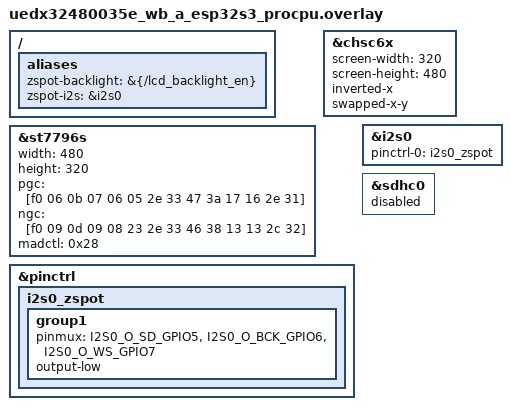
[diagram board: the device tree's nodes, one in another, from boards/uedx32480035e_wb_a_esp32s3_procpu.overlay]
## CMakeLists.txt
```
# Copyright (c) 2026 Muhammad Waleed Badar
# SPDX-License-Identifier: GPL-3.0-only

cmake_minimum_required(VERSION 3.20.0)

# When built from another west workspace, point Zephyr at this module.
if(NOT DEFINED ZEPHYR_EXTRA_MODULES)
  set(ZEPHYR_EXTRA_MODULES ${CMAKE_CURRENT_SOURCE_DIR}/..)
endif()

find_package(Zephyr REQUIRED HINTS $ENV{ZEPHYR_BASE})
project(zspot_player)

target_sources(app PRIVATE src/main.c)
target_sources_ifdef(CONFIG_WIFI_CREDENTIALS_CONNECT_STORED app PRIVATE src/wifi.c)
target_sources_ifdef(CONFIG_ZSPOT_PCM_TAP app PRIVATE src/pcm_tap.c)
target_sources_ifdef(CONFIG_ZSPOT_BATTERY app PRIVATE src/battery.c)
target_sources_ifdef(CONFIG_ZSPOT_UI app PRIVATE
  src/ui.c src/cover.c src/library.c src/webapi.c src/lyrics.c src/json_scan.c)
if(CONFIG_I2S_NATIVE_SIM)
  # Starts the host player the I2S driver writes into; built against the host
  # libc in the runner context.
  target_sources(native_simulator INTERFACE src/pcm_command_bottom.c)

  # Tell when the player is missing, rather than running without sound.
  if(NOT "${CONFIG_ZSPOT_PCM_COMMAND}" STREQUAL "")
    string(REGEX MATCH "^[^ ]+" pcm_player "${CONFIG_ZSPOT_PCM_COMMAND}")
    find_program(PCM_PLAYER_${pcm_player} ${pcm_player})
    if(NOT PCM_PLAYER_${pcm_player})
      message(WARNING "\"${pcm_player}\" (CONFIG_ZSPOT_PCM_COMMAND) was not found "
                      "on this host: the simulator will run without sound.")
    endif()
  endif()
endif()
```

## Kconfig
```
# Copyright (c) 2026 Muhammad Waleed Badar
# SPDX-License-Identifier: GPL-3.0-only

mainmenu "zspot player"

menu "zspot player"

config ZSPOT_PCM_COMMAND
	string "Host command that plays the audio (native_sim)"
	depends on I2S_NATIVE_SIM
	default "aplay -q -f S16_LE -r 44100 -c 2"
	help
	  On native_sim the audio goes through the file-backed I2S driver.
	  When this is set, the simulator starts the shell command at boot and
	  the driver writes into its standard input: raw 16-bit little-endian
	  stereo PCM at 44.1 kHz. Clear it to write the audio to the file
	  I2S_NATIVE_SIM_TX_FILE_PATH instead, or to the one given on the
	  command line with --<i2s device>_tx=<path>.

# The I2S driver opens a path: with a player, the pipe to its standard input
# is installed at this descriptor (src/pcm_command_bottom.c).
config I2S_NATIVE_SIM_TX_FILE_PATH
	default "/dev/fd/200" if ZSPOT_PCM_COMMAND != ""

config ZSPOT_PCM_TAP
	bool "PCM tap: copy of the audio over TCP"
	select RING_BUFFER_LARGE
	help
	  Starts a TCP server that sends a copy of the PCM handed to the sink
	  (16-bit little-endian stereo at 44.1 kHz, before the sink applies the
	  volume) to a client, to hear on another machine what the output is
	  fed with:

	    nc <device> <port> | aplay -f S16_LE -r 44100 -c 2 \
	        -B 1000000 -R 1000000

	  A diagnostic aid: when the copy sounds right but the DAC does not,
	  the fault is in the I2S configuration, the wiring or the DAC.

config ZSPOT_PCM_TAP_PORT
	int "TCP port of the PCM tap"
	default 5000
	depends on ZSPOT_PCM_TAP

config ZSPOT_USERNAME
	string "Spotify username (development only)"
	default ""
	help
	  Together with ZSPOT_PASSWORD, logs in with a username and
	  password instead of the zeroconf hand-over. Spotify no longer accepts
	  password logins from third-party clients for most accounts, but the
	  attempt still exercises access point resolution, the handshake and
	  the authentication exchange, which is useful on native_sim.

config ZSPOT_PASSWORD
	string "Spotify password (development only)"
	default ""

config ZSPOT_CREDENTIALS_JSON
	string "Stored credentials (JSON)"
	default ""
	help
	  Output of zspot_credentials_save_json() from a previous session. When
	  set, the sample skips the zeroconf hand-over.

# The defaults come from the environment of the build, so that the values stay
# out of the repository and of the command line.

config ZSPOT_WEB_CLIENT_ID
	string "Client ID of the Spotify developer application"
	default "$(ZSPOT_WEB_CLIENT_ID)"
	help
	  "Your Library" on the Now Playing screen uses the Spotify Web API,
	  which needs an application registered at developer.spotify.com and a
	  one-time authorisation by the user with scripts/spotify_authorize.py.
	  The three values default to the environment variables
	  ZSPOT_WEB_CLIENT_ID, ZSPOT_WEB_CLIENT_SECRET and
	  ZSPOT_WEB_REFRESH_TOKEN. Without them the library view only says that
	  it is not set up.

config ZSPOT_WEB_CLIENT_SECRET
	string "Client secret of the Spotify developer application"
	default "$(ZSPOT_WEB_CLIENT_SECRET)"

config ZSPOT_WEB_REFRESH_TOKEN
	string "Refresh token of the authorised user"
	default "$(ZSPOT_WEB_REFRESH_TOKEN)"

config ZSPOT_UI
	bool "Now Playing screen (LVGL)"
	depends on LVGL && LV_Z_RUN_LVGL_ON_WORKQUEUE && LV_USE_TJPGD
	help
	  Shows the cover art, title, artist and progress of the current track
	  on the chosen display (the layout follows its resolution) and offers touch
	  controls for play/pause, skipping, seeking and the volume. See
	  prj.conf for the LVGL configuration it needs.

if ZSPOT_UI

config ZSPOT_BATTERY
	bool "Battery indicator"
	default y
	depends on $(dt_alias_enabled,fuel-gauge0)
	select FUEL_GAUGE
	help
	  Shows the charge level reported by the fuel gauge behind the
	  devicetree alias fuel-gauge0 next to the network indicator. Only
	  available when the board has that alias and its node is enabled.

config ZSPOT_BATTERY_POLL_SECONDS
	int "Seconds between two readings of the fuel gauge"
	default 30
	range 1 3600

config ZSPOT_SCREEN_TIMEOUT_SECONDS
	int "Seconds without a touch after which the screen turns off"
	default 60
	range 0 3600
	help
	  Turns the display off, and its backlight when the board has the
	  devicetree alias zspot-backlight (a regulator), once the screen has
	  not been touched for this long. The next touch turns it back on and
	  does nothing else. Playback is not affected. 0 keeps the screen on.

endif # ZSPOT_UI

endmenu # zspot player

source "Kconfig.zephyr"
```

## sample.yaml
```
# Copyright (c) 2026 Muhammad Waleed Badar
# SPDX-License-Identifier: GPL-3.0-only

sample:
  name: zspot player
  description: Spotify Connect player with a touchscreen UI (Now Playing, library, lyrics, Wi-Fi setup)
tests:
  app.zspot.player:
    build_only: true
    tags: zspot
    platform_allow:
      - native_sim/native/64
      - uedx32480035e_wb_a/esp32s3/procpu
    integration_platforms:
      - native_sim/native/64
```

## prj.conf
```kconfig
# Copyright (c) 2026 Muhammad Waleed Badar
# SPDX-License-Identifier: GPL-3.0-only

# --- zspot ---------------------------------------------------------------
CONFIG_ZSPOT=y
CONFIG_ZSPOT_I2S_SINK=y

# --- C++ runtime for the protocol core -----------------------------------
CONFIG_CPP=y
CONFIG_STD_CPP20=y

# --- Memory ---------------------------------------------------------------
CONFIG_MAIN_STACK_SIZE=8192
# Wi-Fi connect requests run on the system workqueue; the ESP32 driver starts
# up in the caller's context and overflows the 1 KB default.
CONFIG_SYSTEM_WORKQUEUE_STACK_SIZE=4096
CONFIG_DYNAMIC_THREAD_POOL_SIZE=0
CONFIG_DYNAMIC_THREAD_PREFER_ALLOC=y

# --- Networking -----------------------------------------------------------
CONFIG_NETWORKING=y
CONFIG_NET_IPV4=y
CONFIG_NET_IPV6=n
CONFIG_NET_TCP=y
CONFIG_NET_UDP=y
CONFIG_NET_SOCKETS=y
CONFIG_NET_DHCPV4=y
CONFIG_NET_MGMT=y
CONFIG_NET_MGMT_EVENT=y
CONFIG_NET_MGMT_EVENT_INFO=y
CONFIG_NET_CONNECTION_MANAGER=n
CONFIG_NET_HOSTNAME_ENABLE=y
CONFIG_NET_HOSTNAME="zspot"
# The TCP receive window is a third of the RX buffer space (128 bytes each).
# With 64 buffers it was 2.7 KB, less than two segments, which throttled the
# audio download; 768 buffers make it 32 KB.
CONFIG_NET_PKT_RX_COUNT=64
CONFIG_NET_BUF_RX_COUNT=768
CONFIG_NET_PKT_TX_COUNT=64
CONFIG_NET_BUF_TX_COUNT=768
CONFIG_NET_MAX_CONN=12
CONFIG_NET_MAX_CONTEXTS=12

CONFIG_NET_RX_STACK_SIZE=4096
CONFIG_NET_TCP_WORKQ_STACK_SIZE=4096

CONFIG_ZVFS_OPEN_MAX=20
CONFIG_ZVFS_POLL_MAX=16

# DNS: resolver gets the servers from DHCP, static fallback below
CONFIG_DNS_RESOLVER=y
CONFIG_DNS_SERVER_IP_ADDRESSES=y
CONFIG_DNS_SERVER1="8.8.8.8"
CONFIG_DNS_RESOLVER_MAX_SERVERS=3
# At a track change the audio CDN, the cover, the lyrics and the Web API are
# looked up at the same time; with the default of one query at a time the
# others fail at once ("DNS lookup ... failed (-3)")
CONFIG_DNS_NUM_CONCUR_QUERIES=4

# mDNS / DNS-SD for discovery by the Spotify app
CONFIG_MDNS_RESPONDER=y
CONFIG_DNS_SD=y
CONFIG_MDNS_RESPONDER_DNS_SD=y

# --- TLS (Spotify endpoints: TLS 1.2, ECDHE-RSA, AES-GCM) -----------------
CONFIG_MBEDTLS=y
CONFIG_MBEDTLS_ENABLE_HEAP=y
# Sessions: access point resolution/metadata, audio CDN and the cover art
CONFIG_MBEDTLS_HEAP_SIZE=163840
CONFIG_MBEDTLS_SSL_IN_CONTENT_LEN=16384
CONFIG_MBEDTLS_SSL_OUT_CONTENT_LEN=4096
CONFIG_MBEDTLS_SSL_PROTO_TLS1_2=y
CONFIG_MBEDTLS_SSL_SERVER_NAME_INDICATION=y
CONFIG_MBEDTLS_KEY_EXCHANGE_ECDHE_RSA_ENABLED=y
CONFIG_MBEDTLS_CIPHERSUITE_TLS_ECDHE_RSA_WITH_AES_128_GCM_SHA256=y
CONFIG_MBEDTLS_CIPHERSUITE_TLS_ECDHE_RSA_WITH_AES_256_GCM_SHA384=y
# The lyrics service (lrclib.net) only offers ECDSA certificates
CONFIG_MBEDTLS_KEY_EXCHANGE_ECDHE_ECDSA_ENABLED=y
CONFIG_MBEDTLS_CIPHERSUITE_TLS_ECDHE_ECDSA_WITH_AES_128_GCM_SHA256=y
CONFIG_MBEDTLS_X509_CRT_PARSE_C=y
CONFIG_PSA_CRYPTO=y
CONFIG_PSA_WANT_ALG_SHA_256=y
CONFIG_PSA_WANT_ALG_SHA_384=y
CONFIG_PSA_WANT_ALG_GCM=y
CONFIG_PSA_WANT_ALG_ECDH=y
CONFIG_PSA_WANT_ECC_SECP_R1_256=y
CONFIG_PSA_WANT_ECC_SECP_R1_384=y
CONFIG_PSA_WANT_KEY_TYPE_ECC_KEY_PAIR_GENERATE=y
CONFIG_PSA_WANT_ALG_RSA_PKCS1V15_SIGN=y
CONFIG_PSA_WANT_ALG_ECDSA=y
CONFIG_PSA_WANT_KEY_TYPE_ECC_PUBLIC_KEY=y
CONFIG_PSA_WANT_KEY_TYPE_RSA_PUBLIC_KEY=y
CONFIG_NET_SOCKETS_SOCKOPT_TLS=y
CONFIG_NET_SOCKETS_TLS_MAX_CONTEXTS=6
CONFIG_ENTROPY_GENERATOR=y

# --- Display: "Now Playing" screen (LVGL) ----------------------------------
CONFIG_DISPLAY=y
CONFIG_INPUT=y
# Touch events queue up while the LVGL thread is busy (e.g. in a zspot call);
# with the default sizes drags lose events ("Could not put input data into
# queue")
CONFIG_INPUT_QUEUE_MAX_MSGS=64
CONFIG_LV_Z_POINTER_INPUT_MSGQ_COUNT=64
CONFIG_LVGL=y
CONFIG_LV_Z_POINTER_INPUT=y
# LVGL runs on its own workqueue; the touch handlers call into zspot from it
# (protobuf encoding, socket I/O), hence the stack
CONFIG_LV_Z_RUN_LVGL_ON_WORKQUEUE=y
CONFIG_LV_Z_LVGL_MUTEX=y
CONFIG_LV_Z_LVGL_WORKQUEUE_STACK_SIZE=16384
# Below the zspot threads (CONFIG_ZSPOT_THREAD_PRIORITY and higher): drawing
# must not take the processor from the audio decoder
CONFIG_LV_Z_LVGL_WORKQUEUE_PRIORITY=8
# Holds the widgets, the cover art (the downloaded JPEG, up to 96 KB, and the
# decoded RGB565 image, 180 KB at 300x300, briefly two of the latter), the
# Web API responses of the library view (160 KB) and the lyrics (80 KB while
# they load)
CONFIG_LV_Z_FLUSH_THREAD=y
CONFIG_LV_Z_FLUSH_THREAD_PRIORITY=8
CONFIG_LV_Z_MEM_POOL_SIZE=1048576
CONFIG_LV_USE_LABEL=y
CONFIG_LV_USE_IMAGE=y
CONFIG_LV_USE_BAR=y
CONFIG_LV_USE_SLIDER=y
# Password entry of the Wi-Fi settings
CONFIG_LV_USE_TEXTAREA=y
CONFIG_LV_USE_BUTTONMATRIX=y
CONFIG_LV_USE_KEYBOARD=y
CONFIG_LV_THEME_DEFAULT_DARK=y
CONFIG_LV_USE_TJPGD=y
CONFIG_LV_FONT_MONTSERRAT_12=y
CONFIG_LV_FONT_MONTSERRAT_14=y
CONFIG_LV_FONT_MONTSERRAT_20=y
CONFIG_LV_FONT_MONTSERRAT_28=y
# One and a half times and twice the size, for displays larger than the
# 320x480 the UI is drawn for (the layout scales with the resolution)
CONFIG_LV_FONT_MONTSERRAT_18=y
CONFIG_LV_FONT_MONTSERRAT_30=y
CONFIG_LV_FONT_MONTSERRAT_24=y
CONFIG_LV_FONT_MONTSERRAT_40=y
CONFIG_LV_FONT_MONTSERRAT_48=y
CONFIG_ZSPOT_UI=y

# --- Wi-Fi (wifi_credentials library, settings/NVS backend) ----------------
# The Wi-Fi driver is selected per board; boards without Wi-Fi override this
# block (see boards/native_sim_native_64.conf).
CONFIG_WIFI=y
CONFIG_WIFI_CREDENTIALS=y
CONFIG_WIFI_CREDENTIALS_CONNECT_STORED=y
CONFIG_FLASH=y
CONFIG_FLASH_MAP=y
CONFIG_NVS=y
CONFIG_SETTINGS=y
CONFIG_NET_MGMT_EVENT_QUEUE_SIZE=16
CONFIG_NET_MGMT_EVENT_STACK_SIZE=4096

# --- Speed ----------------------------------------------------------------
CONFIG_SPEED_OPTIMIZATIONS=y

# --- Logging --------------------------------------------------------------
# Off to save processor time and memory: the console then reports nothing,
# not even I2S underruns or fatal errors. To turn it on, build with
# CONFIG_LOG=y and, for the library, CONFIG_ZSPOT_LOG_LEVEL_INF=y.
CONFIG_NET_LOG=n
CONFIG_LOG_MODE_IMMEDIATE=n
```

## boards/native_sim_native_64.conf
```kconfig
# Copyright (c) 2026 Muhammad Waleed Badar
# SPDX-License-Identifier: GPL-3.0-only
#
# native_sim/native/64: Zephyr IP stack over the host TAP interface (zeth). Create it
# on the host first with net-tools: sudo tools/net-tools/net-setup.sh
# Zephyr uses 192.0.2.1, the host side is 192.0.2.2 (gateway and NAT).

CONFIG_NET_L2_ETHERNET=y
CONFIG_ETH_NATIVE_TAP=y
CONFIG_NET_DHCPV4=n
CONFIG_NET_CONFIG_SETTINGS=y
CONFIG_NET_CONFIG_NEED_IPV4=y
CONFIG_NET_CONFIG_MY_IPV4_ADDR="192.0.2.1"
CONFIG_NET_CONFIG_MY_IPV4_NETMASK="255.255.255.0"
CONFIG_NET_CONFIG_MY_IPV4_GW="192.0.2.2"
CONFIG_NET_CONFIG_PEER_IPV4_ADDR="192.0.2.2"

# No Wi-Fi and no flash-backed settings: override the generic Wi-Fi block
CONFIG_WIFI=n
CONFIG_WIFI_CREDENTIALS=n
CONFIG_WIFI_CREDENTIALS_CONNECT_STORED=n
CONFIG_SETTINGS=n
CONFIG_NVS=n
CONFIG_FLASH=n
CONFIG_FLASH_MAP=n

# The audio goes through the file-backed native_sim I2S driver (the zspot-i2s
# alias in the overlay) into the player named by CONFIG_ZSPOT_PCM_COMMAND, by
# default aplay (alsa-utils). Build with -DCONFIG_ZSPOT_PCM_COMMAND="" to write
# it to the file i2s_out.pcm, or the one given with --i2s_tx_tx=<path>, instead.
# Host RAM is plentiful: buffer ahead of the output as on the ESP32, so that
# the output keeps running while the player fetches the next piece of a track.
CONFIG_ZSPOT_I2S_BUFFER_MS=2000

# The SDL display (an on-screen window, the mouse acts as the touch screen) is
# ARGB8888
CONFIG_LV_COLOR_DEPTH_32=y

# Protocol thread stacks are heap allocated; host RAM is plentiful
CONFIG_HEAP_MEM_POOL_SIZE=262144

CONFIG_ENTROPY_GENERATOR=y
CONFIG_FAKE_ENTROPY_NATIVE_SIM=y
```

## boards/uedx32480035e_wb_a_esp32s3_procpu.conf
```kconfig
# Copyright (c) 2026 Muhammad Waleed Badar
# SPDX-License-Identifier: GPL-3.0-only

# 8 MB octal PSRAM (enabled by the board); keep Wi-Fi and net buffers there too
CONFIG_ESP_WIFI_HEAP_SPIRAM=y
CONFIG_ESP32_WIFI_NET_ALLOC_SPIRAM=y

CONFIG_ESP32_WIFI_STATIC_RX_BUFFER_NUM=8
CONFIG_ESP32_WIFI_DYNAMIC_RX_BUFFER_NUM=16
CONFIG_ESP32_WIFI_DYNAMIC_TX_BUFFER_NUM=16

# I2S slab: 6 blocks of 4 KB
CONFIG_ZSPOT_I2S_BLOCK_COUNT=6

# libc heap in internal RAM (nanopb and small objects; large buffers use PSRAM)
CONFIG_COMMON_LIBC_MALLOC_ARENA_SIZE=40960

# The Mbed TLS heap is relocated to PSRAM (ZSPOT_EXTERNAL_TLS_HEAP_SIZE); keep the static one small
CONFIG_MBEDTLS_HEAP_SIZE=4096

# Now Playing screen: keep LVGL's memory out of internal RAM. The SoC linker
# script places the pool (.lvgl_heap) and the render buffer (.lvgl_buf) in
# PSRAM, and relocates the .bss of the listed libraries there. The UI takes
# its own buffers and the cover loader's stack from the pool.
CONFIG_LV_Z_MEMORY_POOL_CUSTOM_SECTION=y
CONFIG_LV_Z_VDB_CUSTOM_SECTION=y
CONFIG_ESP_SPIRAM_BSS_RELOC_LIBS_AND_OBJS="libmodules__lvgl.a"
```

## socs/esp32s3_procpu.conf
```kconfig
# Copyright (c) 2026 Muhammad Waleed Badar
# SPDX-License-Identifier: GPL-3.0-only

# --- Speed ----------------------------------------------------------------
# Largest caches the ESP32-S3 offers: code runs from flash and every page
# buffer lives in PSRAM, both go through these caches. 64-byte data lines
# suit the renderer's sequential access to tiles and masks.
CONFIG_ESP32S3_INSTRUCTION_CACHE_32KB=y
CONFIG_ESP32S3_INSTRUCTION_CACHE_8WAYS=y
CONFIG_ESP32S3_INSTRUCTION_CACHE_LINE_32B=y
CONFIG_ESP32S3_INSTRUCTION_CACHE_WRAP=y
CONFIG_ESP32S3_DATA_CACHE_64KB=y
CONFIG_ESP32S3_DATA_CACHE_8WAYS=y
CONFIG_ESP32S3_DATA_CACHE_LINE_64B=y
CONFIG_ESP32S3_DATA_CACHE_WRAP=y
# Octal PSRAM and flash at 80 MHz, flash in quad I/O mode
CONFIG_SPIRAM_SPEED_80M=y
CONFIG_ESPTOOLPY_FLASHFREQ_80M=y
CONFIG_ESPTOOLPY_FLASHMODE_QIO=y
# -O3 on top of CONFIG_SPEED_OPTIMIZATIONS (prj.conf); flash has room
CONFIG_COMPILER_OPT="-O3"

# 8 MB octal PSRAM (enabled by the board); keep Wi-Fi and net buffers there too
CONFIG_ESP_WIFI_HEAP_SPIRAM=y
CONFIG_ESP32_WIFI_NET_ALLOC_SPIRAM=y

CONFIG_ESP32_WIFI_STATIC_RX_BUFFER_NUM=8
CONFIG_ESP32_WIFI_DYNAMIC_RX_BUFFER_NUM=16
CONFIG_ESP32_WIFI_DYNAMIC_TX_BUFFER_NUM=16

# libc heap in internal RAM (nanopb and small objects; large buffers use PSRAM)
CONFIG_COMMON_LIBC_MALLOC_ARENA_SIZE=40960

# Now Playing screen: the LVGL memory pool, which also serves the UI's own
# buffers and the stacks of its threads, lives in PSRAM (the SoC linker script
# places the .lvgl_heap section there).
#
# The render buffer stays in internal RAM (30 KB): the display's SPI driver
# sends it with DMA, which cannot read from PSRAM. From there the driver has
# to copy every 4 KB chunk into a buffer from the kernel heap, and fails with
# "Error allocating temp buffer Tx" when that heap is short. For the same
# reason the .bss of the LVGL library, which holds that buffer, is not
# relocated to PSRAM.
CONFIG_LV_Z_MEMORY_POOL_CUSTOM_SECTION=y

# The Mbed TLS heap is relocated to PSRAM (ZSPOT_EXTERNAL_TLS_HEAP_SIZE); keep the static one small
CONFIG_MBEDTLS_HEAP_SIZE=4096
# Audio, cover, lyrics and Web API sessions overlap at a track change; the
# default of 96 KB ran out ("TLS handshake error: -0x8d")
CONFIG_ZSPOT_EXTERNAL_TLS_HEAP_SIZE=262144

# I2S slab: 6 blocks of 4 KB
CONFIG_ZSPOT_I2S_BLOCK_COUNT=6
```

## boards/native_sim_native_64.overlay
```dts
/*
 * Copyright (c) 2026 Muhammad Waleed Badar
 *
 * SPDX-License-Identifier: GPL-3.0-only
 */

/*
 * The audio goes out through the file-backed I2S driver of the board; see
 * CONFIG_ZSPOT_PCM_COMMAND for where.
 */
/ {
	aliases {
		zspot-i2s = &i2s_tx0;
	};
};

&fuel_gauge0 {
	status = "okay";
};

&sdl_dc {
	width = <320>;
	height = <480>;
};
```

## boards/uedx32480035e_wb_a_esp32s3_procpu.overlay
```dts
/*
 * Copyright (c) 2026 Muhammad Waleed Badar
 *
 * SPDX-License-Identifier: GPL-3.0-only
 */

/* Turned off together with the display by the screen timeout. */
/ {
	aliases {
		zspot-backlight = &{/lcd_backlight_en};
		zspot-i2s = &i2s0;
	};
};

/*
 * VIEWE UEDX32480035E-WB-A in landscape (480x320).
 *
 * MADCTL: MV (0x20) exchanges rows and columns, BGR (0x08) is the colour
 * order of the panel. The board's portrait value is 0x48 (MX | BGR). If the
 * picture is upside down for the way the board is mounted, use 0xe8
 * (MY | MX | MV | BGR), and for the touch "inverted-y" instead of
 * "inverted-x".
 */
&st7796s {
	width = <480>;
	height = <320>;
	pgc = [f0 06 0b 07 06 05 2e 33 47 3a 17 16 2e 31];
	ngc = [f0 09 0d 09 08 23 2e 33 46 38 13 13 2c 32];
	madctl = <0x28>;
};

/*
 * The touch controller keeps reporting in the panel's own 320x480 space,
 * which screen-width and screen-height describe. Landscape x is the panel's
 * y, and landscape y runs against the panel's x.
 */
&chsc6x {
	screen-width = <320>;
	screen-height = <480>;
	inverted-x;
	swapped-x-y;
};

&pinctrl {
	i2s0_zspot: i2s0_zspot {
		group1 {
			pinmux = <I2S0_O_SD_GPIO5>,	/* DIN */
				 <I2S0_O_BCK_GPIO6>,
				 <I2S0_O_WS_GPIO7>;	/* LRC */

			output-low;
		};
	};
};

&i2s0 {
	status = "okay";
	pinctrl-0 = <&i2s0_zspot>;
	pinctrl-names = "default";
};

/* Not needed by the player; frees the SDMMC pins and driver memory. */
&sdhc0 {
	status = "disabled";
};
```

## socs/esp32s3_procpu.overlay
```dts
/*
 * Copyright (c) 2026 Muhammad Waleed Badar
 *
 * SPDX-License-Identifier: GPL-3.0-only
 */

/*
 * VIEWE UEDX32480035E-WB-A (ESP32-S3): external I2S DAC on free GPIOs.
 * DATA = GPIO5, BCK = GPIO6, WS (LRCK) = GPIO7. The remaining GPIOs are used
 * by the display, touch, SD card, USB, RGB LED and buzzer.
 */

/ {
	aliases {
		zspot-i2s = &i2s0;
	};
};

&pinctrl {
	i2s0_zspot: i2s0_zspot {
		group1 {
			pinmux = <I2S0_O_SD_GPIO5>,	/* DIN */
				 <I2S0_O_BCK_GPIO6>,
				 <I2S0_O_WS_GPIO7>;	/* LRC */

			output-low;
		};
	};
};

&i2s0 {
	status = "okay";
	pinctrl-0 = <&i2s0_zspot>;
	pinctrl-names = "default";
};

/* Not needed by the player; frees the SDMMC pins and driver memory. */
&sdhc0 {
	status = "disabled";
};
```

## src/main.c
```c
/*
 * Copyright (c) 2026 Muhammad Waleed Badar
 *
 * SPDX-License-Identifier: GPL-3.0-only
 */

/*
 * zspot player: Spotify Connect receiver with I2S output and a touchscreen UI.
 *
 * Flow: bring the network up, advertise the device, wait for the Spotify app
 * to hand over credentials (or use stored ones), connect, and route decoded
 * PCM to the I2S sink. With CONFIG_ZSPOT_UI a "Now Playing" screen shows
 * the track and controls playback.
 */
#include <errno.h>
#include <stdbool.h>
#include <string.h>

#include <zephyr/device.h>
#include <zephyr/kernel.h>
#include <zephyr/sys/atomic.h>
#include <zephyr/logging/log.h>
#include <zephyr/net/net_event.h>
#include <zephyr/net/net_if.h>
#include <zephyr/net/net_mgmt.h>
#include <zephyr/net/dhcpv4.h>

#include <zspot/zspot.h>

#if defined(CONFIG_WIFI_CREDENTIALS_CONNECT_STORED)
#include "wifi.h"
#endif
#if defined(CONFIG_ZSPOT_I2S_SINK)
#include <zspot/zspot_i2s_sink.h>
#endif
#if defined(CONFIG_I2S_NATIVE_SIM)
#include "pcm_command_bottom.h"
#endif
#include "pcm_tap.h"
#include "ui.h"
#include "battery.h"
#if defined(CONFIG_ZSPOT_UI)
#include "library.h"
#include "lyrics.h"
#endif

/* Decoded PCM: 44.1 kHz, 16 bit, stereo */
#define PCM_BYTES_PER_SECOND (44100 * 4)

LOG_MODULE_REGISTER(zspot_player, LOG_LEVEL_INF);

static K_SEM_DEFINE(ipv4_ready, 0, 1);
static struct net_mgmt_event_callback net_cb;

static volatile bool paused;

/*
 * Playback position: where the track was (re)started plus the PCM handed to
 * the sink since then.
 */
static volatile uint32_t position_base_ms;
static atomic_t position_bytes;
/* PLAYBACK_START already set the position of the track that begins next */
static bool position_preset;

static void position_set(uint32_t position_ms)
{
	position_base_ms = position_ms;
	atomic_clear(&position_bytes);
}

/* Polled by the Now Playing screen */
static __maybe_unused uint32_t position_get(void)
{
	int64_t bytes = atomic_get(&position_bytes);

#if defined(CONFIG_ZSPOT_I2S_SINK)
	/* What the sink still holds is not audible yet. */
	bytes = MAX(bytes - (int64_t)zspot_i2s_sink_buffered(), 0);
#endif
	return position_base_ms + (uint32_t)(bytes * 1000 / PCM_BYTES_PER_SECOND);
}

static void net_event_handler(struct net_mgmt_event_callback *cb, uint64_t event,
			      struct net_if *iface)
{
	ARG_UNUSED(cb);
	ARG_UNUSED(iface);

	if (event == NET_EVENT_IPV4_ADDR_ADD) {
		k_sem_give(&ipv4_ready);
	}
}

static int network_connect(void)
{
	struct net_if *iface = net_if_get_default();

	if (iface == NULL) {
		LOG_ERR("No network interface");
		return -ENODEV;
	}

	net_mgmt_init_event_callback(&net_cb, net_event_handler, NET_EVENT_IPV4_ADDR_ADD);
	net_mgmt_add_event_callback(&net_cb);

#if defined(CONFIG_WIFI_CREDENTIALS_CONNECT_STORED)
	/* Credentials come from the wifi_credentials library (settings backend). */
	int ret = wifi_init();

	if (ret != 0) {
		LOG_ERR("Wi-Fi init failed (%d)", ret);
		return ret;
	}
#endif

#if defined(CONFIG_NET_DHCPV4)
	/* The client waits for the interface to come up before sending DISCOVER. */
	net_dhcpv4_start(iface);
#endif

	/* A static address (CONFIG_NET_CONFIG_SETTINGS) is assigned before main() runs. */
	if (net_if_ipv4_get_global_addr(iface, NET_ADDR_PREFERRED) == NULL) {
		LOG_INF("Waiting for an IPv4 address...");
		k_sem_take(&ipv4_ready, K_FOREVER);
	}
	LOG_INF("Network ready");
	ui_set_network(true);
	return 0;
}

static void sink_flush(void)
{
#if defined(CONFIG_ZSPOT_I2S_SINK)
	zspot_i2s_sink_flush();
#endif
}

static void sink_set_volume(uint16_t volume)
{
#if defined(CONFIG_ZSPOT_I2S_SINK)
	zspot_i2s_sink_set_volume(volume);
#else
	ARG_UNUSED(volume);
#endif
}

static int sink_init(void)
{
#if defined(CONFIG_ZSPOT_I2S_SINK)
#if defined(CONFIG_I2S_NATIVE_SIM)
	const char *path = CONFIG_I2S_NATIVE_SIM_TX_FILE_PATH;
	int ret;

	/* The I2S driver writes the audio to a host file: the player's input. */
	if (CONFIG_ZSPOT_PCM_COMMAND[0] == '\0') {
		LOG_INF("Writing the audio to %s (--%s_tx=<path> overrides)", path,
			DEVICE_DT_NAME(DT_ALIAS(zspot_i2s)));
	} else if ((ret = pcm_command_start(CONFIG_ZSPOT_PCM_COMMAND, path)) == 0) {
		LOG_INF("Playing the audio with \"%s\"", CONFIG_ZSPOT_PCM_COMMAND);
	} else if (ret == -EINVAL) {
		LOG_WRN("\"%s\" is not started: the audio goes to %s", CONFIG_ZSPOT_PCM_COMMAND,
			path);
	} else {
		LOG_WRN("Cannot start \"%s\" (%d): running without sound",
			CONFIG_ZSPOT_PCM_COMMAND, ret);
	}
#endif
	return zspot_i2s_sink_init(DEVICE_DT_GET(DT_ALIAS(zspot_i2s)),
				   DEVICE_DT_GET_OR_NULL(DT_ALIAS(zspot_codec)), 44100, 2, 16);
#else
	return 0;
#endif
}

static size_t sink_write(const uint8_t *pcm, size_t len, void *user_data)
{
#if defined(CONFIG_ZSPOT_I2S_SINK)
	return zspot_i2s_sink_write(pcm, len, user_data);
#else
	ARG_UNUSED(pcm);
	ARG_UNUSED(user_data);
	return len;
#endif
}

static void on_event(const struct zspot_event *event, void *user_data)
{
	ARG_UNUSED(user_data);

	switch (event->type) {
	case ZSPOT_EVENT_PLAY_PAUSE:
		LOG_INF("%s", event->paused ? "Paused" : "Playing");
		paused = event->paused;
#if defined(CONFIG_ZSPOT_I2S_SINK)
		zspot_i2s_sink_set_paused(event->paused);
#endif
		ui_set_paused(event->paused);
		break;
	case ZSPOT_EVENT_VOLUME:
		LOG_INF("Volume %u", event->volume);
		sink_set_volume(event->volume);
		ui_set_volume(event->volume);
		break;
	case ZSPOT_EVENT_TRACK_INFO:
		LOG_INF("Now playing: %s - %s (%s)", event->track.artist, event->track.name,
			event->track.album);
		ui_show_track(event->track.name, event->track.artist, event->track.image_url,
			      event->track.duration_ms);
		break;
	case ZSPOT_EVENT_SEEK:
		LOG_INF("Seek to %u ms", event->position_ms);
		sink_flush();
		position_set(event->position_ms);
		break;
	case ZSPOT_EVENT_FLUSH:
		sink_flush();
		break;
	case ZSPOT_EVENT_PLAYBACK_START:
		sink_flush();
		position_set(event->position_ms);
		position_preset = true;
		break;
	case ZSPOT_EVENT_TRACK_BEGIN:
		/* A gapless transition comes without PLAYBACK_START. */
		if (!position_preset) {
			position_set(0);
		}
		position_preset = false;
		zspot_notify_audio_reached_playback();
		break;
	case ZSPOT_EVENT_QUEUE_CHANGED:
		break;
	case ZSPOT_EVENT_DISCONNECT:
		LOG_INF("Playback moved to another device");
		sink_flush();
		ui_show_message("Playing on another device",
				"Pick this device in Spotify to listen here");
		break;
	case ZSPOT_EVENT_NEXT:
	case ZSPOT_EVENT_PREV:
		sink_flush();
		break;
	case ZSPOT_EVENT_DEPLETED:
		LOG_INF("Queue finished");
		break;
	case ZSPOT_EVENT_REPEAT:
		LOG_INF("Repeat %s", event->repeat == ZSPOT_REPEAT_TRACK ? "track"
				     : event->repeat == ZSPOT_REPEAT_ALL ? "all"
									  : "off");
		ui_set_repeat((enum ui_repeat)event->repeat);
		break;
	case ZSPOT_EVENT_CONNECTION_LOST:
		LOG_WRN("Connection to Spotify lost, reconnecting");
		ui_set_network(false);
		break;
	case ZSPOT_EVENT_CONNECTION_RESTORED:
		LOG_INF("Connection to Spotify restored");
		ui_set_network(true);
		break;
	}
}

static size_t on_pcm(const uint8_t *pcm, size_t len, void *user_data)
{
	size_t accepted;

	if (paused) {
		return 0; /* player retries shortly */
	}

	accepted = sink_write(pcm, len, user_data);
	atomic_add(&position_bytes, accepted);
	pcm_tap_write(pcm, accepted);
	return accepted;
}

#if defined(CONFIG_ZSPOT_UI)
static void ui_next(void)
{
	if (zspot_next()) {
		sink_flush();
	}
}

static void ui_previous(void)
{
	if (zspot_previous()) {
		sink_flush();
	}
}

/* The button shows the modes of the library under its own names */
BUILD_ASSERT((int)UI_REPEAT_OFF == (int)ZSPOT_REPEAT_OFF &&
	     (int)UI_REPEAT_ALL == (int)ZSPOT_REPEAT_ALL &&
	     (int)UI_REPEAT_TRACK == (int)ZSPOT_REPEAT_TRACK);

static void ui_repeat(enum ui_repeat mode)
{
	zspot_set_repeat((enum zspot_repeat)mode);
}

static void ui_volume(uint16_t volume, bool commit)
{
	sink_set_volume(volume);
	if (commit) {
		zspot_set_volume(volume);
	}
}

#if !defined(CONFIG_WIFI_CREDENTIALS_CONNECT_STORED)
/* Boards without Wi-Fi, such as native_sim, are connected by other means. */
static void wifi_scan(void)
{
	ui_list_reset(UI_LIST_WIFI, 1, "Wi-Fi", true, "This board has no Wi-Fi");
}

static void wifi_join(const char *ssid, const char *password)
{
	ARG_UNUSED(ssid);
	ARG_UNUSED(password);
}

static void wifi_forget(const char *ssid)
{
	ARG_UNUSED(ssid);
}
#endif

static const struct ui_ops ui_ops = {
	.set_paused = zspot_set_pause,
	.next = ui_next,
	.previous = ui_previous,
	.set_repeat = ui_repeat,
	.seek = zspot_seek,
	.set_volume = ui_volume,
	.position_ms = position_get,
	.library_open = library_open,
	.library_back = library_back,
	.library_select = library_select,
	.wifi_scan = wifi_scan,
	.wifi_connect = wifi_join,
	.wifi_forget = wifi_forget,
	.lyrics_request = lyrics_request,
	.search = library_search,
	.search_select = library_search_select,
};
#endif

int main(void)
{
	static char credentials[1024];
	const struct zspot_config config = {
		.device_name = CONFIG_ZSPOT_DEVICE_NAME,
		.audio_format = ZSPOT_FORMAT_OGG_VORBIS_160,
		.initial_volume = 0xFFFF, /* unity gain at the sink */
	};
	int ret;

#if defined(CONFIG_ZSPOT_UI)
	if (ui_init(&ui_ops) == 0) {
		library_init();
		lyrics_init();
	}
#endif
	battery_init();
	ui_show_message("Connecting", "Waiting for the network");

	if (network_connect() != 0) {
		return 0;
	}

	pcm_tap_init();

	ret = zspot_init(&config);
	if (ret != 0) {
		LOG_ERR("zspot_init failed (%d)", ret);
		return 0;
	}

	ret = sink_init();
	if (ret != 0) {
		LOG_ERR("Audio sink init failed (%d)", ret);
		return 0;
	}

	if (strlen(CONFIG_ZSPOT_CREDENTIALS_JSON) > 0 &&
	    zspot_credentials_load_json(CONFIG_ZSPOT_CREDENTIALS_JSON) == 0) {
		LOG_INF("Using stored credentials");
	} else if (strlen(CONFIG_ZSPOT_USERNAME) > 0 &&
		   zspot_credentials_set_user_pass(CONFIG_ZSPOT_USERNAME,
						   CONFIG_ZSPOT_PASSWORD) == 0) {
		LOG_INF("Using username/password credentials");
	} else {
		ret = zspot_zeroconf_start();
		if (ret != 0) {
			LOG_ERR("Zeroconf start failed (%d)", ret);
			return 0;
		}
	}

	while (true) {
		if (!zspot_credentials_available()) {
			LOG_INF("Open Spotify and select \"%s\" in the device list",
				zspot_device_name());
			ui_show_message(zspot_device_name(),
					"Open Spotify and pick this device");
			zspot_zeroconf_wait(-1);
		}

		ui_show_message("Connecting", "Signing in to Spotify");
		ret = zspot_connect(on_event, on_pcm, NULL);
		if (ret == 0) {
			break;
		}

		LOG_ERR("zspot_connect failed (%d)", ret);
		if (ret == -EACCES) {
			/* Rejected credentials: go back to waiting for a hand-over. */
			zspot_credentials_clear();
		} else {
			k_sleep(K_SECONDS(5));
		}
	}

	if (zspot_credentials_save_json(credentials, sizeof(credentials)) > 0) {
		LOG_INF("Reusable credentials (store these): %s", credentials);
	}

	ui_show_message("Ready", "Pick this device in Spotify to start playing");

	/* Everything else happens on the library threads. */
	return 0;
}
```

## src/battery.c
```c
/*
 * Copyright (c) 2026 Muhammad Waleed Badar
 *
 * SPDX-License-Identifier: GPL-3.0-only
 */

#include <zephyr/device.h>
#include <zephyr/devicetree.h>
#include <zephyr/drivers/fuel_gauge.h>
#include <zephyr/kernel.h>
#include <zephyr/logging/log.h>

#include "battery.h"
#include "ui.h"

LOG_MODULE_REGISTER(battery, LOG_LEVEL_INF);

static const struct device *const gauge = DEVICE_DT_GET(DT_ALIAS(fuel_gauge0));

static void battery_poll(struct k_work *work);
static K_WORK_DELAYABLE_DEFINE(battery_work, battery_poll);

static void battery_poll(struct k_work *work)
{
	union fuel_gauge_prop_val val;
	int ret = fuel_gauge_get_prop(gauge, FUEL_GAUGE_RELATIVE_STATE_OF_CHARGE_PCT, &val);

	if (ret == 0) {
		ui_set_battery(val.relative_state_of_charge_pct);
	} else {
		/* No reading, e.g. the battery was removed: no indicator */
		LOG_DBG("Fuel gauge read failed: %d", ret);
		ui_set_battery(-1);
	}

	k_work_reschedule(&battery_work, K_SECONDS(CONFIG_ZSPOT_BATTERY_POLL_SECONDS));
}

void battery_init(void)
{
	if (!device_is_ready(gauge)) {
		LOG_WRN("Fuel gauge %s is not ready", gauge->name);
		return;
	}

	k_work_reschedule(&battery_work, K_NO_WAIT);
}
```

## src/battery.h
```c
/*
 * Copyright (c) 2026 Muhammad Waleed Badar
 *
 * SPDX-License-Identifier: GPL-3.0-only
 */

/**
 * @file
 * Battery indicator: reads the charge level from the fuel gauge behind the
 * devicetree alias fuel-gauge0 and shows it on the screen. Compiled in only
 * when the board has such a fuel gauge.
 */

#ifndef ZSPOT_SAMPLE_BATTERY_H_
#define ZSPOT_SAMPLE_BATTERY_H_

#if defined(CONFIG_ZSPOT_BATTERY)

/** Starts reading the fuel gauge periodically. Call after ui_init(). */
void battery_init(void);

#else

static inline void battery_init(void)
{
}

#endif /* CONFIG_ZSPOT_BATTERY */

#endif /* ZSPOT_SAMPLE_BATTERY_H_ */
```

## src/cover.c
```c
/*
 * Copyright (c) 2026 Muhammad Waleed Badar
 *
 * SPDX-License-Identifier: GPL-3.0-only
 */

/*
 * Cover art loader: downloads the JPEG on its own thread (the transfer takes
 * a TLS handshake) and decodes it into an RGB565 image with the TJpgDec copy
 * that ships with LVGL. Spotify serves baseline JPEGs, 300x300 for the
 * default size, which is what TJpgDec supports.
 */

#include "cover.h"

#include <errno.h>
#include <string.h>

#include <zephyr/kernel.h>
#include <zephyr/logging/log.h>

#include <lvgl_zephyr.h>
#include <libs/tjpgd/tjpgd.h>

#include <zspot/zspot.h>

LOG_MODULE_DECLARE(zspot_player, LOG_LEVEL_INF);

#define COVER_URL_MAX    128
#define COVER_JPEG_MAX   (96 * 1024)
/* Larger images are decimated while decoding to stay below this edge length */
#define COVER_EDGE_MAX   320
#define COVER_STACK_SIZE 8192
#define COVER_PRIORITY   10
/* TJpgDec needs about 3.5 KB for a colour image */
#define JPEG_POOL_SIZE   4096

struct jpeg_session {
	const uint8_t *data;
	size_t len;
	size_t pos;

	lv_draw_buf_t *image;
	uint32_t step;
	uint32_t sum[3];
};

struct cover_request {
	atomic_val_t generation;
	char url[COVER_URL_MAX];
};

K_MSGQ_DEFINE(cover_requests, sizeof(struct cover_request), 1, 4);

/* Bumped by every request; a result of an older generation is stale. */
static atomic_t cover_generation;
static cover_ready_cb_t cover_ready_cb;

/*
 * The thread stack and the decoder's work area come from the LVGL pool, which
 * boards with external RAM place there.
 */
static struct k_thread cover_thread_data;
static uint8_t *jpeg_pool;

static size_t jpeg_input(JDEC *jd, uint8_t *buf, size_t len)
{
	struct jpeg_session *session = jd->device;

	len = MIN(len, session->len - session->pos);
	if (buf != NULL) {
		memcpy(buf, &session->data[session->pos], len);
	}
	session->pos += len;
	return len;
}

static int jpeg_output(JDEC *jd, void *bitmap, JRECT *rect)
{
	struct jpeg_session *session = jd->device;
	const lv_image_header_t *header = &session->image->header;
	const uint8_t *bgr = bitmap;

	for (uint32_t y = rect->top; y <= rect->bottom; y++) {
		for (uint32_t x = rect->left; x <= rect->right; x++, bgr += 3) {
			uint32_t dx = x / session->step;
			uint32_t dy = y / session->step;
			uint16_t *row;

			if (x % session->step != 0 || y % session->step != 0 ||
			    dx >= header->w || dy >= header->h) {
				continue;
			}

			row = (uint16_t *)(session->image->data + dy * header->stride);
			row[dx] = ((bgr[2] & 0xF8) << 8) | ((bgr[1] & 0xFC) << 3) | (bgr[0] >> 3);

			session->sum[0] += bgr[2];
			session->sum[1] += bgr[1];
			session->sum[2] += bgr[0];
		}
	}
	return 1;
}

static lv_draw_buf_t *cover_decode(const uint8_t *jpeg, size_t len, lv_color_t *accent)
{
	struct jpeg_session session = {.data = jpeg, .len = len, .step = 1};
	uint32_t pixels;
	JRESULT res;
	JDEC jd;

	res = jd_prepare(&jd, jpeg_input, jpeg_pool, JPEG_POOL_SIZE, &session);
	if (res != JDR_OK || jd.width == 0 || jd.height == 0) {
		LOG_WRN("Cover is not a baseline JPEG (%d)", res);
		return NULL;
	}

	while (MAX(jd.width, jd.height) / session.step > COVER_EDGE_MAX) {
		session.step++;
	}

	lvgl_lock();
	session.image = lv_draw_buf_create(MAX(jd.width / session.step, 1),
					   MAX(jd.height / session.step, 1),
					   LV_COLOR_FORMAT_RGB565, LV_STRIDE_AUTO);
	lvgl_unlock();
	if (session.image == NULL) {
		LOG_WRN("No memory for a %ux%u cover", jd.width, jd.height);
		return NULL;
	}

	res = jd_decomp(&jd, jpeg_output, 0);
	if (res != JDR_OK) {
		LOG_WRN("Cover decoding failed (%d)", res);
		lvgl_lock();
		lv_draw_buf_destroy(session.image);
		lvgl_unlock();
		return NULL;
	}

	pixels = session.image->header.w * session.image->header.h;
	*accent = lv_color_make(session.sum[0] / pixels, session.sum[1] / pixels,
				session.sum[2] / pixels);
	return session.image;
}

static void cover_thread(void *p1, void *p2, void *p3)
{
	static struct cover_request request;

	ARG_UNUSED(p1);
	ARG_UNUSED(p2);
	ARG_UNUSED(p3);

	while (true) {
		lv_draw_buf_t *image = NULL;
		lv_color_t accent;
		uint8_t *jpeg;
		int len;

		/* cover_request() purging the queue ends the wait without a message. */
		if (k_msgq_get(&cover_requests, &request, K_FOREVER) != 0) {
			continue;
		}

		lvgl_lock();
		jpeg = lv_malloc(COVER_JPEG_MAX);
		lvgl_unlock();
		if (jpeg == NULL) {
			LOG_WRN("No memory for the cover download");
			continue;
		}

		len = zspot_http_get(request.url, jpeg, COVER_JPEG_MAX);
		if (len > 0) {
			image = cover_decode(jpeg, len, &accent);
		} else {
			LOG_WRN("Cover download failed (%d)", len);
		}

		lvgl_lock();
		lv_free(jpeg);
		if (image != NULL) {
			/* The track may have changed during the download. */
			if (request.generation == atomic_get(&cover_generation)) {
				cover_ready_cb(image, accent);
			} else {
				lv_draw_buf_destroy(image);
			}
		}
		lvgl_unlock();
	}
}

int cover_init(cover_ready_cb_t ready_cb)
{
	uint8_t *stack = lv_malloc(K_KERNEL_STACK_LEN(COVER_STACK_SIZE) + Z_KERNEL_STACK_OBJ_ALIGN);

	jpeg_pool = lv_malloc(JPEG_POOL_SIZE);
	if (stack == NULL || jpeg_pool == NULL) {
		return -ENOMEM;
	}

	cover_ready_cb = ready_cb;
	k_thread_create(&cover_thread_data,
			(k_thread_stack_t *)ROUND_UP(stack, Z_KERNEL_STACK_OBJ_ALIGN),
			COVER_STACK_SIZE, cover_thread, NULL, NULL, NULL, COVER_PRIORITY, 0,
			K_NO_WAIT);
	k_thread_name_set(&cover_thread_data, "cover");
	return 0;
}

void cover_request(const char *url)
{
	struct cover_request request = {.generation = atomic_inc(&cover_generation) + 1};

	k_msgq_purge(&cover_requests);
	if (url == NULL || url[0] == '\0') {
		return;
	}
	if (strlen(url) >= sizeof(request.url)) {
		LOG_WRN("Cover URL too long");
		return;
	}

	strcpy(request.url, url);
	k_msgq_put(&cover_requests, &request, K_NO_WAIT);
}
```

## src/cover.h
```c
/*
 * Copyright (c) 2026 Muhammad Waleed Badar
 *
 * SPDX-License-Identifier: GPL-3.0-only
 */

#ifndef ZSPOT_SAMPLE_COVER_H_
#define ZSPOT_SAMPLE_COVER_H_

#include <lvgl.h>

/**
 * Called with the LVGL lock held once a requested cover was downloaded and
 * decoded. Ownership of @p image passes to the callee, which releases it with
 * lv_draw_buf_destroy(). @p accent is the average colour of the image.
 */
typedef void (*cover_ready_cb_t)(lv_draw_buf_t *image, lv_color_t accent);

/**
 * Starts the cover loader thread. Call with the LVGL lock held.
 * @return 0 on success, -ENOMEM when the LVGL pool is exhausted.
 */
int cover_init(cover_ready_cb_t ready_cb);

/**
 * Requests the JPEG behind @p url. A request that is still queued or being
 * processed is superseded: only the most recent one reaches the callback.
 * NULL or an empty URL just cancels the outstanding request.
 */
void cover_request(const char *url);

#endif /* ZSPOT_SAMPLE_COVER_H_ */
```

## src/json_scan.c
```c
/*
 * Copyright (c) 2026 Muhammad Waleed Badar
 *
 * SPDX-License-Identifier: GPL-3.0-only
 */

#include "json_scan.h"

#include <ctype.h>
#include <stdlib.h>
#include <string.h>

static const char *skip_space(const char *p)
{
	while (*p == ' ' || *p == '\t' || *p == '\n' || *p == '\r') {
		p++;
	}
	return p;
}

/* Returns the character after the closing quote, or NULL. */
static const char *skip_string(const char *p)
{
	for (p++; *p != '\0'; p++) {
		if (*p == '\\' && p[1] != '\0') {
			p++;
		} else if (*p == '"') {
			return p + 1;
		}
	}
	return NULL;
}

/* Returns the character after the value starting at @p p, or NULL. */
static const char *skip_value(const char *p)
{
	int depth = 0;

	do {
		p = skip_space(p);
		switch (*p) {
		case '\0':
			return NULL;
		case '"':
			p = skip_string(p);
			if (p == NULL) {
				return NULL;
			}
			break;
		case '{':
		case '[':
			depth++;
			p++;
			break;
		case '}':
		case ']':
			depth--;
			p++;
			break;
		case ',':
		case ':':
			if (depth == 0) {
				return p; /* empty value: malformed, stop here */
			}
			p++;
			break;
		default: /* number, true, false, null */
			while (*p != '\0' && strchr(",:]} \t\r\n", *p) == NULL) {
				p++;
			}
			break;
		}
	} while (depth > 0);

	return p;
}

const char *json_member(const char *object, const char *key)
{
	size_t key_len = strlen(key);
	const char *p;

	if (object == NULL || *object != '{') {
		return NULL;
	}

	p = skip_space(object + 1);
	while (*p == '"') {
		const char *name = p + 1;
		const char *value;

		p = skip_string(p);
		if (p == NULL) {
			return NULL;
		}
		value = skip_space(p);
		if (*value != ':') {
			return NULL;
		}
		value = skip_space(value + 1);

		/* Keys of the Web API contain no escapes, so compare them raw. */
		if ((size_t)(p - 1 - name) == key_len && memcmp(name, key, key_len) == 0) {
			return value;
		}

		p = skip_value(value);
		if (p == NULL) {
			return NULL;
		}
		p = skip_space(p);
		if (*p != ',') {
			return NULL;
		}
		p = skip_space(p + 1);
	}
	return NULL;
}

const char *json_first(const char *array)
{
	const char *p;

	if (array == NULL || *array != '[') {
		return NULL;
	}
	p = skip_space(array + 1);
	return *p == ']' || *p == '\0' ? NULL : p;
}

const char *json_next(const char *element)
{
	const char *p;

	if (element == NULL) {
		return NULL;
	}
	p = skip_value(element);
	if (p == NULL) {
		return NULL;
	}
	p = skip_space(p);
	return *p == ',' ? skip_space(p + 1) : NULL;
}

static size_t put_utf8(uint32_t code, char *out)
{
	if (code < 0x80) {
		out[0] = code;
		return 1;
	}
	if (code < 0x800) {
		out[0] = 0xC0 | (code >> 6);
		out[1] = 0x80 | (code & 0x3F);
		return 2;
	}
	if (code < 0x10000) {
		out[0] = 0xE0 | (code >> 12);
		out[1] = 0x80 | ((code >> 6) & 0x3F);
		out[2] = 0x80 | (code & 0x3F);
		return 3;
	}
	out[0] = 0xF0 | (code >> 18);
	out[1] = 0x80 | ((code >> 12) & 0x3F);
	out[2] = 0x80 | ((code >> 6) & 0x3F);
	out[3] = 0x80 | (code & 0x3F);
	return 4;
}

/* Reads the four hex digits of a \u escape; false when they are not there. */
static bool read_hex4(const char *p, uint32_t *code)
{
	*code = 0;
	for (int i = 0; i < 4; i++) {
		if (!isxdigit((unsigned char)p[i])) {
			return false;
		}
		*code = *code * 16 + (isdigit((unsigned char)p[i])
					      ? p[i] - '0'
					      : tolower((unsigned char)p[i]) - 'a' + 10);
	}
	return true;
}

bool json_string(const char *value, char *out, size_t size)
{
	size_t len = 0;
	const char *p;

	out[0] = '\0';
	if (value == NULL || *value != '"') {
		return false;
	}

	for (p = value + 1; *p != '\0' && *p != '"';) {
		char utf8[4];
		size_t n = 1;

		if (*p != '\\') {
			/* Copy a whole UTF-8 sequence so truncation cannot split it. */
			utf8[0] = *p++;
			while (((uint8_t)*p & 0xC0) == 0x80 && n < sizeof(utf8)) {
				utf8[n++] = *p++;
			}
		} else {
			uint32_t code;
			uint32_t low;

			p++;
			switch (*p) {
			case 'n':
				utf8[0] = '\n';
				break;
			case 't':
				utf8[0] = '\t';
				break;
			case 'r':
				utf8[0] = '\r';
				break;
			case 'b':
			case 'f':
				utf8[0] = ' ';
				break;
			case 'u':
				if (!read_hex4(p + 1, &code)) {
					return len > 0;
				}
				p += 4;
				/* Surrogate pair for characters beyond the BMP */
				if (code >= 0xD800 && code < 0xDC00 && p[1] == '\\' &&
				    p[2] == 'u' && read_hex4(p + 3, &low) && low >= 0xDC00 &&
				    low < 0xE000) {
					code = 0x10000 + ((code - 0xD800) << 10) + (low - 0xDC00);
					p += 6;
				}
				n = put_utf8(code, utf8);
				break;
			case '\0':
				return len > 0;
			default: /* quote, backslash, slash */
				utf8[0] = *p;
				break;
			}
			p++;
		}

		if (len + n >= size) {
			break;
		}
		memcpy(&out[len], utf8, n);
		len += n;
		out[len] = '\0';
	}
	return true;
}

uint32_t json_uint(const char *value, uint32_t fallback)
{
	if (value == NULL || !isdigit((unsigned char)*value)) {
		return fallback;
	}
	return strtoul(value, NULL, 10);
}
```

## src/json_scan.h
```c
/*
 * Copyright (c) 2026 Muhammad Waleed Badar
 *
 * SPDX-License-Identifier: GPL-3.0-only
 */

/*
 * Minimal read-only JSON walker for picking a few fields out of large Web API
 * responses without building a tree. The document must be NUL terminated. A
 * value is referred to by a pointer to its first character; NULL means
 * "absent" and is accepted by every function, so lookups can be chained.
 */

#ifndef ZSPOT_SAMPLE_JSON_SCAN_H_
#define ZSPOT_SAMPLE_JSON_SCAN_H_

#include <stdbool.h>
#include <stddef.h>
#include <stdint.h>

/** Value of @p key in the object @p object, or NULL. */
const char *json_member(const char *object, const char *key);

/** First element of the array @p array, or NULL when it is empty. */
const char *json_first(const char *array);

/** Element following @p element in its array, or NULL after the last one. */
const char *json_next(const char *element);

/**
 * Decodes the string @p value into @p out, truncating at a character
 * boundary. Returns false (and an empty @p out) when it is not a string.
 */
bool json_string(const char *value, char *out, size_t size);

/** Non-negative integer @p value, or @p fallback when it is not a number. */
uint32_t json_uint(const char *value, uint32_t fallback);

#endif /* ZSPOT_SAMPLE_JSON_SCAN_H_ */
```

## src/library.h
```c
/*
 * Copyright (c) 2026 Muhammad Waleed Badar
 *
 * SPDX-License-Identifier: GPL-3.0-only
 */

/*
 * "Your Library" and the search: lists the user's Liked Songs and playlists
 * through the Spotify Web API, the tracks of the one that is picked, or the
 * songs that match a search, and starts playback of a track on this device. The listings are shown with
 * ui_list_reset() / ui_list_add(); the functions below are the matching
 * struct ui_ops hooks and only queue work for the library thread.
 */

#ifndef ZSPOT_SAMPLE_LIBRARY_H_
#define ZSPOT_SAMPLE_LIBRARY_H_

/** Starts the library thread. Call after ui_init() succeeded. */
int library_init(void);

/** Loads and shows the top level: Liked Songs and the playlists. */
void library_open(void);

/** Returns from a track listing to the top level without reloading it. */
void library_back(void);

/**
 * Row @p index of the current listing was picked: opens that collection, or
 * plays that track of the open collection.
 */
void library_select(int index);

/** Searches for songs and lists the hits (UI_LIST_SEARCH). */
void library_search(const char *query);

/** Plays the hit @p index of the last search, followed by the hits after it. */
void library_search_select(int index);

#endif /* ZSPOT_SAMPLE_LIBRARY_H_ */
```

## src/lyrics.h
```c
/*
 * Copyright (c) 2026 Muhammad Waleed Badar
 *
 * SPDX-License-Identifier: GPL-3.0-only
 */

/*
 * Lyrics from LRCLIB (https://lrclib.net), a free service that needs no
 * account. They are looked up by title, artist and duration on a thread of
 * their own and handed to the UI with ui_show_lyrics() or, when there are
 * none, ui_set_lyrics_status().
 */

#ifndef ZSPOT_SAMPLE_LYRICS_H_
#define ZSPOT_SAMPLE_LYRICS_H_

#include <stdint.h>

/** Starts the lyrics thread. Call after ui_init() succeeded. */
int lyrics_init(void);

/**
 * Looks the lyrics of a track up; matches struct ui_ops.lyrics_request. A
 * lookup that is still queued or running is superseded.
 */
void lyrics_request(const char *title, const char *artist, uint32_t duration_ms);

#endif /* ZSPOT_SAMPLE_LYRICS_H_ */
```

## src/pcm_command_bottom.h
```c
/*
 * Copyright (c) 2026 Muhammad Waleed Badar
 *
 * SPDX-License-Identifier: GPL-3.0-only
 */

/* Host side of the native_sim PCM player; only host types in this interface. */

#ifndef ZSPOT_PCM_COMMAND_BOTTOM_H_
#define ZSPOT_PCM_COMMAND_BOTTOM_H_

/**
 * Starts the shell command @p command on the host and installs its standard
 * input at the descriptor number that @p path, the output file of the
 * native_sim I2S driver, names in the form "/dev/fd/<n>".
 *
 * Returns 0 when the command runs, -ENOENT when its program is not installed,
 * -EINVAL when @p path has another form, -EBUSY when the descriptor is in
 * use, or another negative errno. Except for -EINVAL, the driver finds
 * /dev/null at that descriptor after a failure, so that the audio is
 * discarded instead of stalling the simulator.
 */
int pcm_command_start(const char *command, const char *path);

#endif /* ZSPOT_PCM_COMMAND_BOTTOM_H_ */
```
